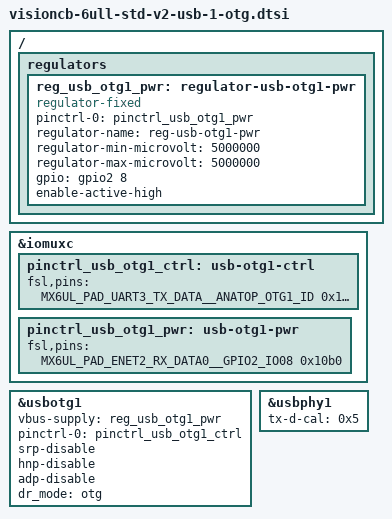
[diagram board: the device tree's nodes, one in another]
/*
 * This program is free software; you can redistribute it and/or modify
 * it under the terms of the GNU General Public License version 2 as
 * published by the Free Software Foundation.
 */

/ {
	/* Regulators */
	regulators {
		/* USB OTG1 */
		reg_usb_otg1_pwr: regulator-usb-otg1-pwr {
			compatible = "regulator-fixed";
			pinctrl-names = "default";
			pinctrl-0 = <&pinctrl_usb_otg1_pwr>;
			regulator-name = "reg-usb-otg1-pwr";
			regulator-min-microvolt = <5000000>;
			regulator-max-microvolt = <5000000>;
			gpio = <&gpio2 8 GPIO_ACTIVE_HIGH>;
			enable-active-high;
		};
        };
};

/* IO multiplexing */
&iomuxc {
	/* USB OTG1 */
	pinctrl_usb_otg1_ctrl: usb-otg1-ctrl {
		fsl,pins = <
			MX6UL_PAD_UART3_TX_DATA__ANATOP_OTG1_ID 0x17059
		>;
	};
	pinctrl_usb_otg1_pwr: usb-otg1-pwr {
		fsl,pins = <
			MX6UL_PAD_ENET2_RX_DATA0__GPIO2_IO08 0x10b0
		>;
	};
};

/* USB OTG1 */
&usbotg1 {
	vbus-supply = <&reg_usb_otg1_pwr>;
	pinctrl-names = "default";
	pinctrl-0 = <&pinctrl_usb_otg1_ctrl>;
	srp-disable;
	hnp-disable;
	adp-disable;
	dr_mode = "otg";
	status = "okay";
};

/* USB PHY1 */
&usbphy1 {
	tx-d-cal = <0x5>;
};
